# MKL02Z4 register map
Vendor: Freescale Semiconductor, Inc.; File version: 1.6
CPU: CM0PLUS r0p0, little endian, no MPU, no FPU, 0x2 interrupt priority bits, 0x0 interrupts
Registers are 32-bit, read-write, reset 0x0 unless marked. A register's access mark holds for its fields unless they carry their own. Offsets are from the block's base; [hi:lo] are bit positions; {n}, {i} and the like mark numbered series; 'fields as' and 'values as' point back to an identical list.

## TPM0 — Timer/PWM Module
Base 0x40038000; register names take the prefix TPM0_
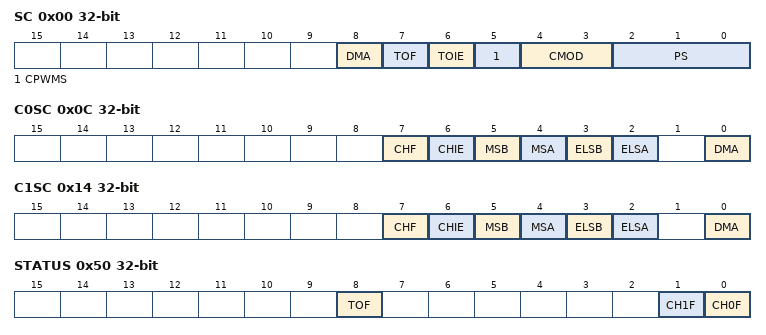
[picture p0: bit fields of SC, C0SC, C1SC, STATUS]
0x00 SC — Status and Control
  [8] DMA — DMA Enable
    0=Disables DMA transfers; 1=Enables DMA transfers
  [7] TOF — Timer Overflow Flag
    0=LPTPM counter has not overflowed; 1=LPTPM counter has overflowed
  [6] TOIE — Timer Overflow Interrupt Enable
    0=Disable TOF interrupts. Use software polling or DMA request.; 1=Enable TOF interrupts. An interrupt is generated when TOF equals one.
  [5] CPWMS — Center-aligned PWM Select
    0=LPTPM counter operates in up counting mode; 1=LPTPM counter operates in up-down counting mode
  [4:3] CMOD — Clock Mode Selection
    0=LPTPM counter is disabled; 1=LPTPM counter increments on every LPTPM counter clock; 2=LPTPM counter increments on rising edge of LPTPM_EXTCLK synchronized to the LPTPM counter clock
  [2:0] PS — Prescale Factor Selection
    0=Divide by 1; 1=Divide by 2; 2=Divide by 4; 3=Divide by 8; 4=Divide by 16; 5=Divide by 32; 6=Divide by 64; 7=Divide by 128
0x04 CNT — Counter
  [15:0] COUNT — Counter value
0x08 MOD reset 0xFFFF — Modulo
  [15:0] MOD — Modulo value
0x0C C0SC — Channel (n) Status and Control
  [7] CHF — Channel Flag
    0=No channel event has occurred; 1=A channel event has occurred
  [6] CHIE — Channel Interrupt Enable
    0=Disable channel interrupts; 1=Enable channel interrupts
  [5] MSB — Channel Mode Select
  [4] MSA — Channel Mode Select
  [3] ELSB — Edge or Level Select
  [2] ELSA — Edge or Level Select
  [0] DMA — DMA Enable
    0=Disable DMA transfers; 1=Enable DMA transfers
0x10 C0V — Channel (n) Value
  [15:0] VAL — Channel Value
0x14 C1SC — Channel (n) Status and Control
  fields as C0SC
0x18 C1V — Channel (n) Value
  [15:0] VAL — Channel Value
0x50 STATUS — Capture and Compare Status
  [8] TOF — Timer Overflow Flag
    values as SC.TOF
  [1] CH1F — Channel 1 Flag
    values as C0SC.CHF
  [0] CH0F — Channel 0 Flag
    values as C0SC.CHF
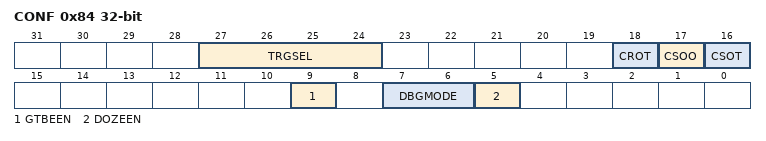
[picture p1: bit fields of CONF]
0x84 CONF — Configuration
  [27:24] TRGSEL — Trigger Select
  [18] CROT — Counter Reload On Trigger
    0=Counter is not reloaded due to a rising edge on the selected input trigger; 1=Counter is reloaded when a rising edge is detected on the selected input trigger
  [17] CSOO — Counter Stop On Overflow
    0=LPTPM counter continues incrementing or decrementing after overflow; 1=LPTPM counter stops incrementing or decrementing after overflow
  [16] CSOT — Counter Start on Trigger
    0=LPTPM counter starts to increment immediately, once it is enabled; 1=LPTPM counter only starts to increment when it a rising edge on the selected input trigger is detected, after it has been enabled or after it has stopped due to overflow
  [9] GTBEEN — Global time base enable
    0=All channels use the internally generated LPTPM counter as their timebase; 1=All channels use an externally generated global timebase as their timebase
  [7:6] DBGMODE — Debug Mode
    0=LPTPM counter is paused and does not increment during debug mode. Trigger inputs and input capture events are also ignored.; 3=LPTPM counter continues in debug mode
  [5] DOZEEN — Doze Enable
    0=Internal LPTPM counter continues in Doze mode; 1=Internal LPTPM counter is paused and does not increment during Doze mode. Trigger inputs and input capture events are also ignored.

## TPM1 — Timer/PWM Module
Base 0x40039000; register names take the prefix TPM1_
Registers as TPM0.

## LPTMR0 — Low Power Timer
Base 0x40040000; register names take the prefix LPTMR0_
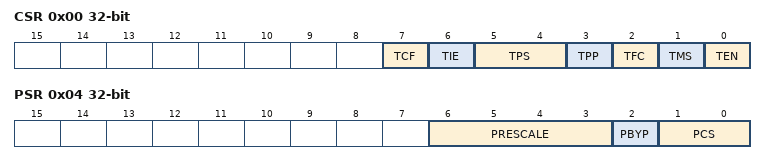
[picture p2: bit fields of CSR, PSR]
0x00 CSR — Low Power Timer Control Status Register
  [7] TCF — Timer Compare Flag
    0=The value of CNR is not equal to CMR and increments; 1=The value of CNR is equal to CMR and increments
  [6] TIE — Timer Interrupt Enable
    0=Timer interrupt disabled; 1=Timer interrupt enabled
  [5:4] TPS — Timer Pin Select
    {v}=Pulse counter input {v} is selected (v=0..3)
  [3] TPP — Timer Pin Polarity
    0=Pulse Counter input source is active-high, and the CNR will increment on the rising-edge; 1=Pulse Counter input source is active-low, and the CNR will increment on the falling-edge
  [2] TFC — Timer Free-Running Counter
    0=CNR is reset whenever TCF is set; 1=CNR is reset on overflow
  [1] TMS — Timer Mode Select
    0=Time Counter mode; 1=Pulse Counter mode
  [0] TEN — Timer Enable
    0=LPTMR is disabled and internal logic is reset; 1=LPTMR is enabled
0x04 PSR — Low Power Timer Prescale Register
  [6:3] PRESCALE — Prescale Value
    0=Prescaler divides the prescaler clock by 2; glitch filter does not support this configuration; 1=Prescaler divides the prescaler clock by 4; glitch filter recognizes change on input pin after 2 rising clock edges; 2=Prescaler divides the prescaler clock by 8; glitch filter recognizes change on input pin after 4 rising clock edges; 3=Prescaler divides the prescaler clock by 16; glitch filter recognizes change on input pin after 8 rising clock edges; 4=Prescaler divides the prescaler clock by 32; glitch filter recognizes change on input pin after 16 rising clock edges; 5=Prescaler divides the prescaler clock by 64; glitch filter recognizes change on input pin after 32 rising clock edges; 6=Prescaler divides the prescaler clock by 128; glitch filter recognizes change on input pin after 64 rising clock edges; 7=Prescaler divides the prescaler clock by 256; glitch filter recognizes change on input pin after 128 rising clock edges; 8=Prescaler divides the prescaler clock by 512; glitch filter recognizes change on input pin after 256 rising clock edges; 9=Prescaler divides the prescaler clock by 1024; glitch filter recognizes change on input pin after 512 rising clock edges; 10=Prescaler divides the prescaler clock by 2048; glitch filter recognizes change on input pin after 1024 rising clock edges; 11=Prescaler divides the prescaler clock by 4096; glitch filter recognizes change on input pin after 2048 rising clock edges; 12=Prescaler divides the prescaler clock by 8192; glitch filter recognizes change on input pin after 4096 rising clock edges; 13=Prescaler divides the prescaler clock by 16,384; glitch filter recognizes change on input pin after 8192 rising clock edges; 14=Prescaler divides the prescaler clock by 32,768; glitch filter recognizes change on input pin after 16,384 rising clock edges; 15=Prescaler divides the prescaler clock by 65,536; glitch filter recognizes change on input pin after 32,768 rising clock edges
  [2] PBYP — Prescaler Bypass
    0=Prescaler/glitch filter is enabled; 1=Prescaler/glitch filter is bypassed
  [1:0] PCS — Prescaler Clock Select
    {v}=Prescaler/glitch filter clock {v} selected (v=0..3)
0x08 CMR — Low Power Timer Compare Register
  [15:0] COMPARE — Compare Value
0x0C CNR — Low Power Timer Counter Register
  [15:0] COUNTER — Counter Value
